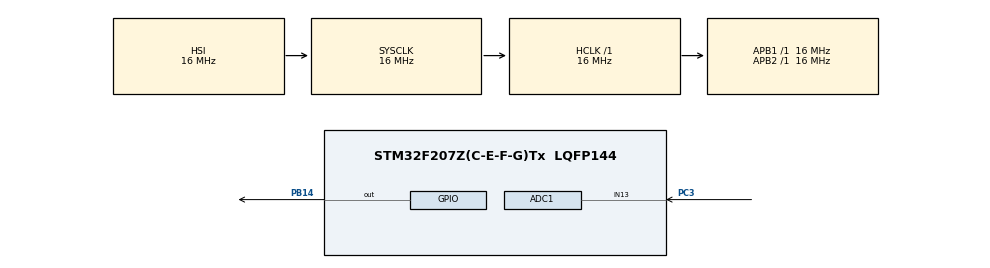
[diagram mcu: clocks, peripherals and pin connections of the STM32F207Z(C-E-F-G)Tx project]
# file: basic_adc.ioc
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ADC1.Channel-0\#ChannelRegularConversion=ADC_CHANNEL_13
ADC1.ExternalTrigConv=ADC_EXTERNALTRIGCONV_T3_TRGO
ADC1.NbrOfConversion=1
ADC1.NbrOfConversionFlag=1
ADC1.Rank-0\#ChannelRegularConversion=1
ADC1.SamplingTime-0\#ChannelRegularConversion=ADC_SAMPLETIME_3CYCLES
ADC1.master=1
Mcu.Family=STM32F2
Mcu.Name=STM32F207Z(C-E-F-G)Tx
Mcu.Package=LQFP144
NVIC.ADC_IRQn=true\:0\:0\:false\:false\:true\:true\:true\:true
NVIC.PriorityGroup=NVIC_PRIORITYGROUP_4
NVIC.TIM3_IRQn=true\:0\:0\:false\:false\:true\:true\:true\:true
PB14.Signal=GPIO_Output
PC3.Signal=ADCx_IN13
ProjectManager.HeapSize=0x200
ProjectManager.StackSize=0x400
ProjectManager.TargetToolchain=STM32CubeIDE
RCC.48MHZClocksFreq_Value=48000000
RCC.AHBFreq_Value=16000000
RCC.APB1Freq_Value=16000000
RCC.APB2Freq_Value=16000000
RCC.CortexFreq_Value=16000000
RCC.HSE_VALUE=25000000
RCC.HSI_VALUE=16000000
RCC.LSE_VALUE=32768
RCC.SYSCLKFreq_VALUE=16000000
RCC.VCOOutputFreq_Value=192000000
SH.ADCx_IN13.0=ADC1_IN13,IN13
TIM3.Channel-PWM\ Generation3\ No\ Output=TIM_CHANNEL_3
TIM3.Period=2000 - 1
TIM3.Prescaler=1600 - 1
TIM3.TIM_MasterOutputTrigger=TIM_TRGO_UPDATE
VP_TIM3_VS_ClockSourceINT.Mode=Internal
VP_TIM3_VS_no_output3.Mode=PWM Generation3 No Output
board=custom

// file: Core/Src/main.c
/* USER CODE BEGIN Header */
/**
  ******************************************************************************
  * @file           : main.c
  * @brief          : Main program body
  ******************************************************************************
  * @attention
  *
  * Copyright (c) 2023 STMicroelectronics.
  * All rights reserved.
  *
  * This software is licensed under terms that can be found in the LICENSE file
  * in the root directory of this software component.
  * If no LICENSE file comes with this software, it is provided AS-IS.
  *
  ******************************************************************************
  */
/* USER CODE END Header */
#include "main.h"

ADC_HandleTypeDef hadc1;

TIM_HandleTypeDef htim3;

/* USER CODE BEGIN PV */
uint16_t adcValue = 0;
float divRatio = 0.00;
/* USER CODE END PV */

void SystemClock_Config(void);
static void MX_GPIO_Init(void);
static void MX_ADC1_Init(void);
static void MX_TIM3_Init(void);

/* USER CODE BEGIN 0 */
void HAL_ADC_ConvCpltCallback(ADC_HandleTypeDef *hadc)
{
	adcValue = HAL_ADC_GetValue(&hadc1);
	divRatio = (float)adcValue / 4095;
	HAL_GPIO_TogglePin(GPIOB, GPIO_PIN_14);
}
/* USER CODE END 0 */

int main(void)
{

  /* MCU Configuration--------------------------------------------------------*/

  /* Reset of all peripherals, Initializes the Flash interface and the Systick. */
  HAL_Init();

  /* Configure the system clock */
  SystemClock_Config();

  /* Initialize all configured peripherals */
  MX_GPIO_Init();
  MX_ADC1_Init();
  MX_TIM3_Init();
  /* USER CODE BEGIN 2 */
HAL_ADC_Start_IT(&hadc1);
HAL_TIM_Base_Start(&htim3);

  /* USER CODE END 2 */

  /* Infinite loop */
  while (1)
  {

  }
}

void SystemClock_Config(void)
{
  RCC_OscInitTypeDef RCC_OscInitStruct = {0};
  RCC_ClkInitTypeDef RCC_ClkInitStruct = {0};

  /** Initializes the RCC Oscillators according to the specified parameters
  * in the RCC_OscInitTypeDef structure.
  */
  RCC_OscInitStruct.OscillatorType = RCC_OSCILLATORTYPE_HSI;
  RCC_OscInitStruct.HSIState = RCC_HSI_ON;
  RCC_OscInitStruct.HSICalibrationValue = RCC_HSICALIBRATION_DEFAULT;
  RCC_OscInitStruct.PLL.PLLState = RCC_PLL_NONE;
  if (HAL_RCC_OscConfig(&RCC_OscInitStruct) != HAL_OK)
  {
    Error_Handler();
  }

  /** Initializes the CPU, AHB and APB buses clocks
  */
  RCC_ClkInitStruct.ClockType = RCC_CLOCKTYPE_HCLK|RCC_CLOCKTYPE_SYSCLK
                              |RCC_CLOCKTYPE_PCLK1|RCC_CLOCKTYPE_PCLK2;
  RCC_ClkInitStruct.SYSCLKSource = RCC_SYSCLKSOURCE_HSI;
  RCC_ClkInitStruct.AHBCLKDivider = RCC_SYSCLK_DIV1;
  RCC_ClkInitStruct.APB1CLKDivider = RCC_HCLK_DIV1;
  RCC_ClkInitStruct.APB2CLKDivider = RCC_HCLK_DIV1;

  if (HAL_RCC_ClockConfig(&RCC_ClkInitStruct, FLASH_LATENCY_0) != HAL_OK)
  {
    Error_Handler();
  }
}

static void MX_ADC1_Init(void)
{

  ADC_ChannelConfTypeDef sConfig = {0};

  /** Configure the global features of the ADC (Clock, Resolution, Data Alignment and number of conversion)
  */
  hadc1.Instance = ADC1;
  hadc1.Init.ClockPrescaler = ADC_CLOCK_SYNC_PCLK_DIV2;
  hadc1.Init.Resolution = ADC_RESOLUTION_12B;
  hadc1.Init.ScanConvMode = DISABLE;
  hadc1.Init.ContinuousConvMode = DISABLE;
  hadc1.Init.DiscontinuousConvMode = DISABLE;
  hadc1.Init.ExternalTrigConvEdge = ADC_EXTERNALTRIGCONVEDGE_RISING;
  hadc1.Init.ExternalTrigConv = ADC_EXTERNALTRIGCONV_T3_TRGO;
  hadc1.Init.DataAlign = ADC_DATAALIGN_RIGHT;
  hadc1.Init.NbrOfConversion = 1;
  hadc1.Init.DMAContinuousRequests = DISABLE;
  hadc1.Init.EOCSelection = ADC_EOC_SINGLE_CONV;
  if (HAL_ADC_Init(&hadc1) != HAL_OK)
  {
    Error_Handler();
  }

  /** Configure for the selected ADC regular channel its corresponding rank in the sequencer and its sample time.
  */
  sConfig.Channel = ADC_CHANNEL_13;
  sConfig.Rank = 1;
  sConfig.SamplingTime = ADC_SAMPLETIME_3CYCLES;
  if (HAL_ADC_ConfigChannel(&hadc1, &sConfig) != HAL_OK)
  {
    Error_Handler();
  }

}

static void MX_TIM3_Init(void)
{

  TIM_ClockConfigTypeDef sClockSourceConfig = {0};
  TIM_MasterConfigTypeDef sMasterConfig = {0};
  TIM_OC_InitTypeDef sConfigOC = {0};

  htim3.Instance = TIM3;
  htim3.Init.Prescaler = 1600 - 1;
  htim3.Init.CounterMode = TIM_COUNTERMODE_UP;
  htim3.Init.Period = 2000 - 1;
  htim3.Init.ClockDivision = TIM_CLOCKDIVISION_DIV1;
  htim3.Init.AutoReloadPreload = TIM_AUTORELOAD_PRELOAD_DISABLE;
  if (HAL_TIM_Base_Init(&htim3) != HAL_OK)
  {
    Error_Handler();
  }
  sClockSourceConfig.ClockSource = TIM_CLOCKSOURCE_INTERNAL;
  if (HAL_TIM_ConfigClockSource(&htim3, &sClockSourceConfig) != HAL_OK)
  {
    Error_Handler();
  }
  if (HAL_TIM_PWM_Init(&htim3) != HAL_OK)
  {
    Error_Handler();
  }
  sMasterConfig.MasterOutputTrigger = TIM_TRGO_UPDATE;
  sMasterConfig.MasterSlaveMode = TIM_MASTERSLAVEMODE_DISABLE;
  if (HAL_TIMEx_MasterConfigSynchronization(&htim3, &sMasterConfig) != HAL_OK)
  {
    Error_Handler();
  }
  sConfigOC.OCMode = TIM_OCMODE_PWM1;
  sConfigOC.Pulse = 0;
  sConfigOC.OCPolarity = TIM_OCPOLARITY_HIGH;
  sConfigOC.OCFastMode = TIM_OCFAST_DISABLE;
  if (HAL_TIM_PWM_ConfigChannel(&htim3, &sConfigOC, TIM_CHANNEL_3) != HAL_OK)
  {
    Error_Handler();
  }

}

static void MX_GPIO_Init(void)
{
  GPIO_InitTypeDef GPIO_InitStruct = {0};

  /* GPIO Ports Clock Enable */
  __HAL_RCC_GPIOC_CLK_ENABLE();
  __HAL_RCC_GPIOB_CLK_ENABLE();

  /*Configure GPIO pin Output Level */
  HAL_GPIO_WritePin(GPIOB, GPIO_PIN_14, GPIO_PIN_RESET);

  /*Configure GPIO pin : PB14 */
  GPIO_InitStruct.Pin = GPIO_PIN_14;
  GPIO_InitStruct.Mode = GPIO_MODE_OUTPUT_PP;
  GPIO_InitStruct.Pull = GPIO_NOPULL;
  GPIO_InitStruct.Speed = GPIO_SPEED_FREQ_LOW;
  HAL_GPIO_Init(GPIOB, &GPIO_InitStruct);

}

void Error_Handler(void)
{
  __disable_irq();
  while (1)
  {
  }
}
